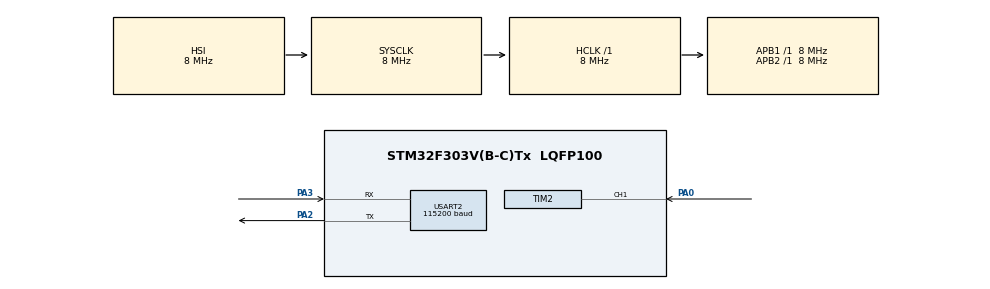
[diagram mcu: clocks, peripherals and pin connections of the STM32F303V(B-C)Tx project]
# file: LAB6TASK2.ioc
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Mcu.Family=STM32F3
Mcu.Name=STM32F303V(B-C)Tx
Mcu.Package=LQFP100
NVIC.PriorityGroup=NVIC_PRIORITYGROUP_4
NVIC.TIM2_IRQn=true\:0\:0\:false\:false\:true\:true\:true\:true
PA0.Signal=S_TIM2_CH1_ETR
PA2.Mode=Asynchronous
PA2.Signal=USART2_TX
PA3.Mode=Asynchronous
PA3.Signal=USART2_RX
ProjectManager.HeapSize=0x200
ProjectManager.StackSize=0x400
ProjectManager.TargetToolchain=CMake
RCC.AHBFreq_Value=8000000
RCC.APB1Freq_Value=8000000
RCC.APB2Freq_Value=8000000
RCC.CortexFreq_Value=8000000
RCC.HSE_VALUE=8000000
RCC.HSI_VALUE=8000000
RCC.LSE_VALUE=32768
RCC.SYSCLKFreq_VALUE=8000000
SH.S_TIM2_CH1_ETR.0=TIM2_CH1,Input_Capture1_from_TI1
TIM2.Channel-Input_Capture1_from_TI1=TIM_CHANNEL_1
TIM2.Prescaler=71
USART2.BaudRate=115200
USART2.VirtualMode-Asynchronous=VM_ASYNC
board=custom

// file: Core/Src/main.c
/* USER CODE BEGIN Header */
/**
  ******************************************************************************
  * @file           : main.c
  * @brief          : Main program body
  ******************************************************************************
  * @attention
  *
  * Copyright (c) 2026 STMicroelectronics.
  * All rights reserved.
  *
  * This software is licensed under terms that can be found in the LICENSE file
  * in the root directory of this software component.
  * If no LICENSE file comes with this software, it is provided AS-IS.
  *
  ******************************************************************************
  */
/* USER CODE END Header */
#include "main.h"
#include <stdio.h>

TIM_HandleTypeDef htim2;

UART_HandleTypeDef huart2;

void SystemClock_Config(void);
static void MX_GPIO_Init(void);
static void MX_TIM2_Init(void);
static void MX_USART2_UART_Init(void);

/* USER CODE BEGIN 0 */
volatile uint32_t ic_val1 = 0;
volatile uint32_t ic_val2= 0;
volatile uint32_t diff = 0;
volatile uint8_t is_first_capture = 0;
uint16_t frequency=0;

char uart_buffer[100];

int _write(int file, char *ptr, int len)
  {
  HAL_UART_Transmit(&huart2, (uint8_t*)ptr, len, HAL_MAX_DELAY);
  return len;
  }

void HAL_TIM_IC_CaptureCallback(TIM_HandleTypeDef *htim)
  {
  if(htim->Channel == HAL_TIM_ACTIVE_CHANNEL_1)
    {
    if(is_first_capture == 0)
      {
      ic_val1 = HAL_TIM_ReadCapturedValue(htim, TIM_CHANNEL_1);
      is_first_capture = 1;
      }
    else
      {
      ic_val2 = HAL_TIM_ReadCapturedValue(htim, TIM_CHANNEL_1);

      if(ic_val2 > ic_val1)
      diff = ic_val2 - ic_val1;
      else
      diff = (0xFFFFFFFF - ic_val1) + ic_val2;

      if(diff > 0 && diff < 50000)
      {
        frequency = 111111/ diff;
      }
      is_first_capture = 0;
      }
    }
  }
/* USER CODE END 0 */

int main(void)
{

  /* MCU Configuration--------------------------------------------------------*/

  /* Reset of all peripherals, Initializes the Flash interface and the Systick. */
  HAL_Init();

  /* Configure the system clock */
  SystemClock_Config();

  /* Initialize all configured peripherals */
  MX_GPIO_Init();
  MX_TIM2_Init();
  MX_USART2_UART_Init();
  /* USER CODE BEGIN 2 */
  HAL_TIM_IC_Start_IT(&htim2, TIM_CHANNEL_1);
  /* USER CODE END 2 */

  /* Infinite loop */
  while (1)
  {
    printf("Freq: %lu Hz\r\n", frequency);
    HAL_Delay(200);
  }
}

void SystemClock_Config(void)
{
  RCC_OscInitTypeDef RCC_OscInitStruct = {0};
  RCC_ClkInitTypeDef RCC_ClkInitStruct = {0};
  RCC_PeriphCLKInitTypeDef PeriphClkInit = {0};

  /** Initializes the RCC Oscillators according to the specified parameters
  * in the RCC_OscInitTypeDef structure.
  */
  RCC_OscInitStruct.OscillatorType = RCC_OSCILLATORTYPE_HSI;
  RCC_OscInitStruct.HSIState = RCC_HSI_ON;
  RCC_OscInitStruct.HSICalibrationValue = RCC_HSICALIBRATION_DEFAULT;
  RCC_OscInitStruct.PLL.PLLState = RCC_PLL_NONE;
  if (HAL_RCC_OscConfig(&RCC_OscInitStruct) != HAL_OK)
  {
    Error_Handler();
  }

  /** Initializes the CPU, AHB and APB buses clocks
  */
  RCC_ClkInitStruct.ClockType = RCC_CLOCKTYPE_HCLK|RCC_CLOCKTYPE_SYSCLK
                              |RCC_CLOCKTYPE_PCLK1|RCC_CLOCKTYPE_PCLK2;
  RCC_ClkInitStruct.SYSCLKSource = RCC_SYSCLKSOURCE_HSI;
  RCC_ClkInitStruct.AHBCLKDivider = RCC_SYSCLK_DIV1;
  RCC_ClkInitStruct.APB1CLKDivider = RCC_HCLK_DIV1;
  RCC_ClkInitStruct.APB2CLKDivider = RCC_HCLK_DIV1;

  if (HAL_RCC_ClockConfig(&RCC_ClkInitStruct, FLASH_LATENCY_0) != HAL_OK)
  {
    Error_Handler();
  }
  PeriphClkInit.PeriphClockSelection = RCC_PERIPHCLK_USART2;
  PeriphClkInit.Usart2ClockSelection = RCC_USART2CLKSOURCE_PCLK1;
  if (HAL_RCCEx_PeriphCLKConfig(&PeriphClkInit) != HAL_OK)
  {
    Error_Handler();
  }
}

static void MX_TIM2_Init(void)
{

  TIM_MasterConfigTypeDef sMasterConfig = {0};
  TIM_IC_InitTypeDef sConfigIC = {0};

  htim2.Instance = TIM2;
  htim2.Init.Prescaler = 71;
  htim2.Init.CounterMode = TIM_COUNTERMODE_UP;
  htim2.Init.Period = 65535;
  htim2.Init.ClockDivision = TIM_CLOCKDIVISION_DIV1;
  htim2.Init.AutoReloadPreload = TIM_AUTORELOAD_PRELOAD_DISABLE;
  if (HAL_TIM_IC_Init(&htim2) != HAL_OK)
  {
    Error_Handler();
  }
  sMasterConfig.MasterOutputTrigger = TIM_TRGO_RESET;
  sMasterConfig.MasterSlaveMode = TIM_MASTERSLAVEMODE_DISABLE;
  if (HAL_TIMEx_MasterConfigSynchronization(&htim2, &sMasterConfig) != HAL_OK)
  {
    Error_Handler();
  }
  sConfigIC.ICPolarity = TIM_INPUTCHANNELPOLARITY_RISING;
  sConfigIC.ICSelection = TIM_ICSELECTION_DIRECTTI;
  sConfigIC.ICPrescaler = TIM_ICPSC_DIV1;
  sConfigIC.ICFilter = 0;
  if (HAL_TIM_IC_ConfigChannel(&htim2, &sConfigIC, TIM_CHANNEL_1) != HAL_OK)
  {
    Error_Handler();
  }

}

static void MX_USART2_UART_Init(void)
{

  huart2.Instance = USART2;
  huart2.Init.BaudRate = 115200;
  huart2.Init.WordLength = UART_WORDLENGTH_8B;
  huart2.Init.StopBits = UART_STOPBITS_1;
  huart2.Init.Parity = UART_PARITY_NONE;
  huart2.Init.Mode = UART_MODE_TX_RX;
  huart2.Init.HwFlowCtl = UART_HWCONTROL_NONE;
  huart2.Init.OverSampling = UART_OVERSAMPLING_16;
  huart2.Init.OneBitSampling = UART_ONE_BIT_SAMPLE_DISABLE;
  huart2.AdvancedInit.AdvFeatureInit = UART_ADVFEATURE_NO_INIT;
  if (HAL_UART_Init(&huart2) != HAL_OK)
  {
    Error_Handler();
  }

}

static void MX_GPIO_Init(void)
{
  /* USER CODE BEGIN MX_GPIO_Init_1 */
  GPIO_InitTypeDef GPIO_InitStruct = {0};
  /* USER CODE END MX_GPIO_Init_1 */

  /* GPIO Ports Clock Enable */
  __HAL_RCC_GPIOA_CLK_ENABLE();

  /* USER CODE BEGIN MX_GPIO_Init_2 */
  GPIO_InitStruct.Pin = GPIO_PIN_0;
  GPIO_InitStruct.Mode = GPIO_MODE_AF_PP;   // Alternate function
  GPIO_InitStruct.Pull = GPIO_PULLDOWN;     // <-- THIS is what you want
  GPIO_InitStruct.Speed = GPIO_SPEED_FREQ_LOW;
  GPIO_InitStruct.Alternate = GPIO_AF1_TIM2;

  HAL_GPIO_Init(GPIOA, &GPIO_InitStruct);
  /* USER CODE END MX_GPIO_Init_2 */
}

void Error_Handler(void)
{
  __disable_irq();
  while (1)
  {
  }
}
